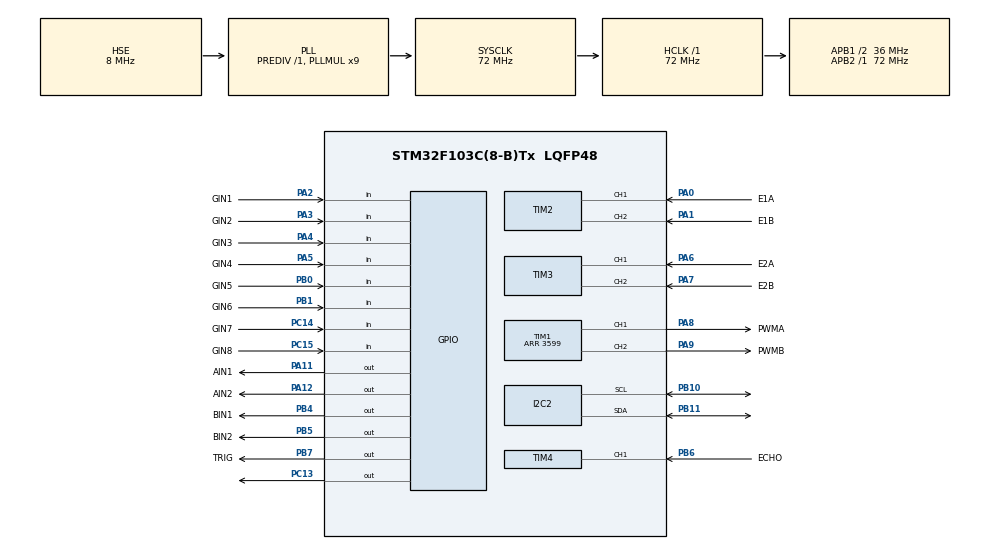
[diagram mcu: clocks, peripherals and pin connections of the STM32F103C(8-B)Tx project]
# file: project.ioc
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I2C2.I2C_Mode=I2C_Fast
Mcu.Family=STM32F1
Mcu.Name=STM32F103C(8-B)Tx
Mcu.Package=LQFP48
NVIC.PriorityGroup=NVIC_PRIORITYGROUP_4
NVIC.TIM4_IRQn=true\:0\:0\:true\:false\:true\:true\:true\:true
PA0-WKUP.GPIO_Label=E1A
PA0-WKUP.Signal=S_TIM2_CH1_ETR
PA1.GPIO_Label=E1B
PA1.Signal=S_TIM2_CH2
PA11.GPIO_Label=AIN1
PA11.Signal=GPIO_Output
PA12.GPIO_Label=AIN2
PA12.Signal=GPIO_Output
PA13.Mode=Serial_Wire
PA13.Signal=SYS_JTMS-SWDIO
PA14.Mode=Serial_Wire
PA14.Signal=SYS_JTCK-SWCLK
PA2.GPIO_Label=GIN1
PA2.Signal=GPIO_Input
PA3.GPIO_Label=GIN2
PA3.Signal=GPIO_Input
PA4.GPIO_Label=GIN3
PA4.Signal=GPIO_Input
PA5.GPIO_Label=GIN4
PA5.Signal=GPIO_Input
PA6.GPIO_Label=E2A
PA6.Signal=S_TIM3_CH1
PA7.GPIO_Label=E2B
PA7.Signal=S_TIM3_CH2
PA8.GPIO_Label=PWMA
PA8.Signal=S_TIM1_CH1
PA9.GPIO_Label=PWMB
PA9.Signal=S_TIM1_CH2
PB0.GPIO_Label=GIN5
PB0.Signal=GPIO_Input
PB1.GPIO_Label=GIN6
PB1.Signal=GPIO_Input
PB10.Mode=I2C
PB10.Signal=I2C2_SCL
PB11.Mode=I2C
PB11.Signal=I2C2_SDA
PB4.GPIO_Label=BIN1
PB4.Signal=GPIO_Output
PB5.GPIO_Label=BIN2
PB5.Signal=GPIO_Output
PB6.GPIO_Label=ECHO
PB6.Signal=S_TIM4_CH1
PB7.GPIO_Label=TRIG
PB7.Signal=GPIO_Output
PC13-TAMPER-RTC.Signal=GPIO_Output
PC14-OSC32_IN.GPIO_Label=GIN7
PC14-OSC32_IN.Signal=GPIO_Input
PC15-OSC32_OUT.GPIO_Label=GIN8
PC15-OSC32_OUT.Signal=GPIO_Input
PD0-OSC_IN.Mode=HSE-External-Oscillator
PD0-OSC_IN.Signal=RCC_OSC_IN
PD1-OSC_OUT.Mode=HSE-External-Oscillator
PD1-OSC_OUT.Signal=RCC_OSC_OUT
ProjectManager.HeapSize=0x200
ProjectManager.StackSize=0x400
ProjectManager.TargetToolchain=CMake
RCC.AHBFreq_Value=72000000
RCC.APB1CLKDivider=RCC_HCLK_DIV2
RCC.APB1Freq_Value=36000000
RCC.APB1TimCLKDivider=2
RCC.APB1TimFreq_Value=72000000
RCC.APB2Freq_Value=72000000
RCC.APB2TimFreq_Value=72000000
RCC.HCLKFreq_Value=72000000
RCC.PLLMUL=RCC_PLL_MUL9
RCC.PLLSourceVirtual=RCC_PLLSOURCE_HSE
RCC.SYSCLKFreq_VALUE=72000000
RCC.SYSCLKSource=RCC_SYSCLKSOURCE_PLLCLK
RCC.USBFreq_Value=72000000
SH.S_TIM1_CH1.0=TIM1_CH1,PWM Generation1 CH1
SH.S_TIM1_CH2.0=TIM1_CH2,PWM Generation2 CH2
SH.S_TIM2_CH1_ETR.0=TIM2_CH1,Encoder_Interface
SH.S_TIM2_CH2.0=TIM2_CH2,Encoder_Interface
SH.S_TIM3_CH1.0=TIM3_CH1,Encoder_Interface
SH.S_TIM3_CH2.0=TIM3_CH2,Encoder_Interface
SH.S_TIM4_CH1.0=TIM4_CH1,Input_Capture1_from_TI1
TIM1.Channel-PWM\ Generation1\ CH1=TIM_CHANNEL_1
TIM1.Channel-PWM\ Generation2\ CH2=TIM_CHANNEL_2
TIM1.Period=3599
TIM2.EncoderMode=TIM_ENCODERMODE_TI12
TIM3.EncoderMode=TIM_ENCODERMODE_TI12
TIM4.Channel-Input_Capture1_from_TI1=TIM_CHANNEL_1
TIM4.Period=9999
TIM4.Prescaler=72-1
VP_TIM4_VS_ClockSourceINT.Mode=Internal
board=custom

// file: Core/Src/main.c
/* USER CODE BEGIN Header */
/**
  ******************************************************************************
  * @file           : main.c
  * @brief          : Main program body
  ******************************************************************************
  * @attention
  *
  * Copyright (c) 2026 STMicroelectronics.
  * All rights reserved.
  *
  * This software is licensed under terms that can be found in the LICENSE file
  * in the root directory of this software component.
  * If no LICENSE file comes with this software, it is provided AS-IS.
  *
  ******************************************************************************
  */
/* USER CODE END Header */
#include "main.h"
#include "i2c.h"
#include "tim.h"
#include "gpio.h"

/* USER CODE BEGIN Includes */
#include "../../User/main_entry/main_entry.h"

/* USER CODE END Includes */

void SystemClock_Config(void);

int main(void)
{

  /* MCU Configuration--------------------------------------------------------*/

  /* Reset of all peripherals, Initializes the Flash interface and the Systick. */
  HAL_Init();

  /* Configure the system clock */
  SystemClock_Config();

  /* Initialize all configured peripherals */
  MX_GPIO_Init();
  MX_TIM1_Init();
  MX_TIM2_Init();
  MX_TIM3_Init();
  MX_TIM4_Init();
  MX_I2C2_Init();

  /* Infinite loop */
  /* USER CODE BEGIN WHILE */
  main_entry();
  while (1)
  {
    /* USER CODE END WHILE */

  }
}

void SystemClock_Config(void)
{
  RCC_OscInitTypeDef RCC_OscInitStruct = {0};
  RCC_ClkInitTypeDef RCC_ClkInitStruct = {0};

  /** Initializes the RCC Oscillators according to the specified parameters
  * in the RCC_OscInitTypeDef structure.
  */
  RCC_OscInitStruct.OscillatorType = RCC_OSCILLATORTYPE_HSE;
  RCC_OscInitStruct.HSEState = RCC_HSE_ON;
  RCC_OscInitStruct.HSEPredivValue = RCC_HSE_PREDIV_DIV1;
  RCC_OscInitStruct.HSIState = RCC_HSI_ON;
  RCC_OscInitStruct.PLL.PLLState = RCC_PLL_ON;
  RCC_OscInitStruct.PLL.PLLSource = RCC_PLLSOURCE_HSE;
  RCC_OscInitStruct.PLL.PLLMUL = RCC_PLL_MUL9;
  if (HAL_RCC_OscConfig(&RCC_OscInitStruct) != HAL_OK)
  {
    Error_Handler();
  }

  /** Initializes the CPU, AHB and APB buses clocks
  */
  RCC_ClkInitStruct.ClockType = RCC_CLOCKTYPE_HCLK|RCC_CLOCKTYPE_SYSCLK
                              |RCC_CLOCKTYPE_PCLK1|RCC_CLOCKTYPE_PCLK2;
  RCC_ClkInitStruct.SYSCLKSource = RCC_SYSCLKSOURCE_PLLCLK;
  RCC_ClkInitStruct.AHBCLKDivider = RCC_SYSCLK_DIV1;
  RCC_ClkInitStruct.APB1CLKDivider = RCC_HCLK_DIV2;
  RCC_ClkInitStruct.APB2CLKDivider = RCC_HCLK_DIV1;

  if (HAL_RCC_ClockConfig(&RCC_ClkInitStruct, FLASH_LATENCY_2) != HAL_OK)
  {
    Error_Handler();
  }
}

void Error_Handler(void)
{
  __disable_irq();
  while (1)
  {
  }
}
